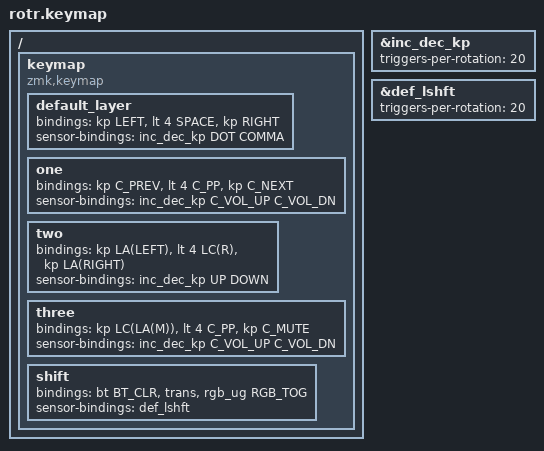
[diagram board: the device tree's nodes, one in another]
#include <behaviors.dtsi>
#include <dt-bindings/zmk/keys.h>
#include <dt-bindings/zmk/rgb.h>
#include <dt-bindings/zmk/bt.h>

&inc_dec_kp {
	triggers-per-rotation = <20>;
};
&def_lshft {
	triggers-per-rotation = <20>;
};

/ {
	keymap {
		compatible = "zmk,keymap";

		default_layer {
			//PREV | PLAY/PAUSE | NEXT || Youtube Control
			bindings = <&kp LEFT &lt 4 SPACE &kp RIGHT>;
			sensor-bindings = <&inc_dec_kp DOT COMMA>;
		};
		one {
			//PREV | PLAY/PAUSE | NEXT || Music Control
			bindings = <&kp C_PREV &lt 4 C_PP &kp C_NEXT>;
			sensor-bindings = <&inc_dec_kp C_VOL_UP C_VOL_DN>;
		};
		two {
			//PREV | PLAY/PAUSE | NEXT || Web Search
			bindings = <&kp LA(LEFT) &lt 4 LC(R) &kp LA(RIGHT)>;
			sensor-bindings = <&inc_dec_kp UP DOWN>;
		};
		three {
			//PREV | PLAY/PAUSE | NEXT || Call Control
			bindings = <&kp LC(LA(M)) &lt 4 C_PP &kp C_MUTE>;
			sensor-bindings = <&inc_dec_kp C_VOL_UP C_VOL_DN>;
		};
		shift {
			//PREV | PLAY/PAUSE | NEXT
			bindings = <&bt BT_CLR &trans &rgb_ug RGB_TOG>;
			sensor-bindings = <&def_lshft>;
		};
	};
};
